# ESP32-C6 register map
Vendor: ESPRESSIF SYSTEMS (SHANGHAI) CO., LTD.; Series: ESP32 C-Series; File version: 12
CPU: RV32IMAC r0p0, little endian, no MPU, no FPU, 0 interrupt priority bits
Address unit: 32 bits
Registers are 32-bit, read-write, reset 0x0 unless marked. A register's access mark holds for its fields unless they carry their own. Offsets are from the block's base; [hi:lo] are bit positions.

## HP_SYS — High-Power System
Base 0x60095000
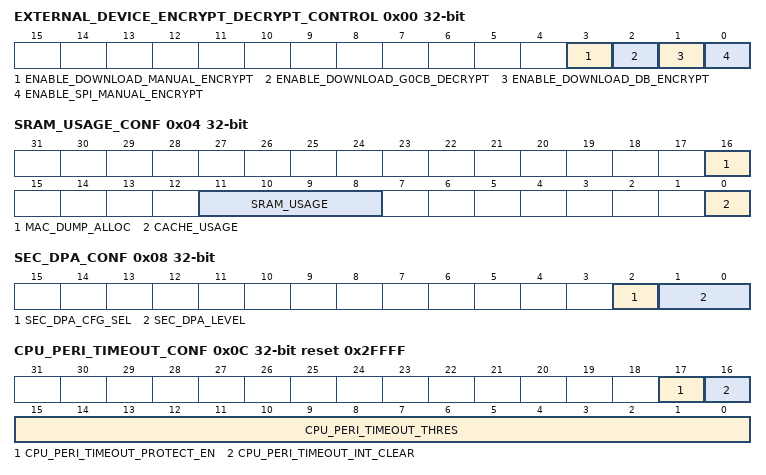
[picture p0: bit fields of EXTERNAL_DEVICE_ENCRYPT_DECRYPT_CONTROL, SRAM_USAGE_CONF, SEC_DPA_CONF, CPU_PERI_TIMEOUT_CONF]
0x00 EXTERNAL_DEVICE_ENCRYPT_DECRYPT_CONTROL — EXTERNAL DEVICE ENCRYPTION/DECRYPTION configuration register
  [3] ENABLE_DOWNLOAD_MANUAL_ENCRYPT — Set this bit as 1 to enable mspi xts manual encrypt in download boot mode.
  [2] ENABLE_DOWNLOAD_G0CB_DECRYPT — Set this bit as 1 to enable mspi xts auto decrypt in download boot mode.
  [1] ENABLE_DOWNLOAD_DB_ENCRYPT — reserved
  [0] ENABLE_SPI_MANUAL_ENCRYPT — Set this bit as 1 to enable mspi xts manual encrypt in spi boot mode.
0x04 SRAM_USAGE_CONF access per field — HP memory usage configuration register
  [16] MAC_DUMP_ALLOC rw — Set this bit as 1 to add an offset (64KB) when mac-dump accessing hp-memory.
  [11:8] SRAM_USAGE rw — 0: cpu use hp-memory. 1:mac-dump accessing hp-memory.
  [0] CACHE_USAGE ro — reserved
0x08 SEC_DPA_CONF — HP anti-DPA security configuration register
  [2] SEC_DPA_CFG_SEL — This field is used to select either HP_SYS_SEC_DPA_LEVEL or EFUSE_SEC_DPA_LEVEL (from efuse) to control dpa_level. 0: EFUSE_SEC_DPA_LEVEL, 1: HP_SYS_SEC_DPA_LEVEL.
  [1:0] SEC_DPA_LEVEL — 0: anti-DPA disable. 1~3: anti-DPA enable with different security level. The larger the number, the stronger the ability to resist DPA attacks and the higher the security level, but it will increase the computational overhead of the hardware crypto-accelerators. Only avaliable if HP_SYS_SEC_DPA_CFG_SEL is 0.
0x0C CPU_PERI_TIMEOUT_CONF access per field reset 0x2FFFF — CPU_PERI_TIMEOUT configuration register
  [17] CPU_PERI_TIMEOUT_PROTECT_EN rw — Set this bit as 1 to enable timeout protection for accessing cpu peripheral registers
  [16] CPU_PERI_TIMEOUT_INT_CLEAR wo — Set this bit as 1 to clear timeout interrupt
  [15:0] CPU_PERI_TIMEOUT_THRES rw — Set the timeout threshold for bus access, corresponding to the number of clock cycles of the clock domain.
0x10 CPU_PERI_TIMEOUT_ADDR ro
  [31:0] CPU_PERI_TIMEOUT_ADDR — Record the address information of abnormal access
0x14 CPU_PERI_TIMEOUT_UID ro
  [6:0] CPU_PERI_TIMEOUT_UID — Record master id[4:0] & master permission[6:5] when trigger timeout. This register will be cleared after the interrupt is cleared.
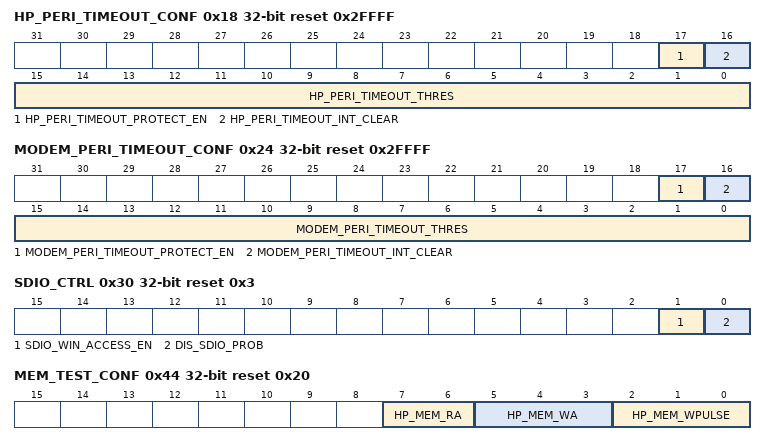
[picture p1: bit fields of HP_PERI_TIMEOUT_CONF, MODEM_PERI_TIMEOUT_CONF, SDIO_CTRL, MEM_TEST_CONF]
0x18 HP_PERI_TIMEOUT_CONF access per field reset 0x2FFFF — HP_PERI_TIMEOUT configuration register
  [17] HP_PERI_TIMEOUT_PROTECT_EN rw — Set this bit as 1 to enable timeout protection for accessing hp peripheral registers
  [16] HP_PERI_TIMEOUT_INT_CLEAR wo — Set this bit as 1 to clear timeout interrupt
  [15:0] HP_PERI_TIMEOUT_THRES rw — Set the timeout threshold for bus access, corresponding to the number of clock cycles of the clock domain.
0x1C HP_PERI_TIMEOUT_ADDR ro
  [31:0] HP_PERI_TIMEOUT_ADDR — Record the address information of abnormal access
0x20 HP_PERI_TIMEOUT_UID ro
  [6:0] HP_PERI_TIMEOUT_UID — Record master id[4:0] & master permission[6:5] when trigger timeout. This register will be cleared after the interrupt is cleared.
0x24 MODEM_PERI_TIMEOUT_CONF access per field reset 0x2FFFF — MODEM_PERI_TIMEOUT configuration register
  [17] MODEM_PERI_TIMEOUT_PROTECT_EN rw — Set this bit as 1 to enable timeout protection for accessing modem registers
  [16] MODEM_PERI_TIMEOUT_INT_CLEAR wo — Set this bit as 1 to clear timeout interrupt
  [15:0] MODEM_PERI_TIMEOUT_THRES rw — Set the timeout threshold for bus access, corresponding to the number of clock cycles of the clock domain.
0x28 MODEM_PERI_TIMEOUT_ADDR ro
  [31:0] MODEM_PERI_TIMEOUT_ADDR — Record the address information of abnormal access
0x2C MODEM_PERI_TIMEOUT_UID ro
  [6:0] MODEM_PERI_TIMEOUT_UID — Record master id[4:0] & master permission[6:5] when trigger timeout. This register will be cleared after the interrupt is cleared.
0x30 SDIO_CTRL reset 0x3 — SDIO Control configuration register
  [1] SDIO_WIN_ACCESS_EN — Enable sdio slave to access other peripherals on the chip
  [0] DIS_SDIO_PROB — Set this bit as 1 to disable SDIO_PROB function. disable by default.
0x34 RETENTION_CONF — Retention configuration register
  [0] RETENTION_DISABLE — Set this bit as 1 to disable retention function. Not disable by default.
0x38 ROM_TABLE_LOCK
  [0] ROM_TABLE_LOCK — XXXX
0x3C ROM_TABLE
  [31:0] ROM_TABLE — XXXX
0x40 CORE_DEBUG_RUNSTALL_CONF — Core Debug runstall configure register
  [0] CORE_DEBUG_RUNSTALL_ENABLE — Set this field to 1 to enable debug runstall feature between HP-core and LP-core.
0x44 MEM_TEST_CONF reset 0x20 — MEM_TEST configuration register
  [7:6] HP_MEM_RA — This field controls hp system memory RA parameter.
  [5:3] HP_MEM_WA — This field controls hp system memory WA parameter.
  [2:0] HP_MEM_WPULSE — This field controls hp system memory WPULSE parameter.
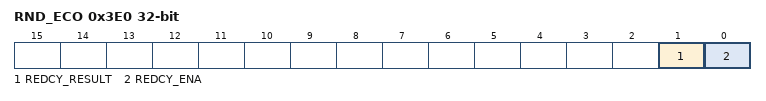
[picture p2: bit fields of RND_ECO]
0x3E0 RND_ECO access per field — redcy eco register.
  [1] REDCY_RESULT ro — Only reserved for ECO.
  [0] REDCY_ENA rw — Only reserved for ECO.
0x3E4 RND_ECO_LOW — redcy eco low register.
  [31:0] REDCY_LOW — Only reserved for ECO.
0x3E8 RND_ECO_HIGH reset 0xFFFFFFFF — redcy eco high register.
  [31:0] REDCY_HIGH — Only reserved for ECO.
0x3F8 CLOCK_GATE — HP-SYSTEM clock gating configure register
  [0] CLK_EN — Set this bit as 1 to force on clock gating.
0x3FC DATE reset 0x2206110
  [27:0] DATE — HP-SYSTEM date information/ HP-SYSTEM version information.
